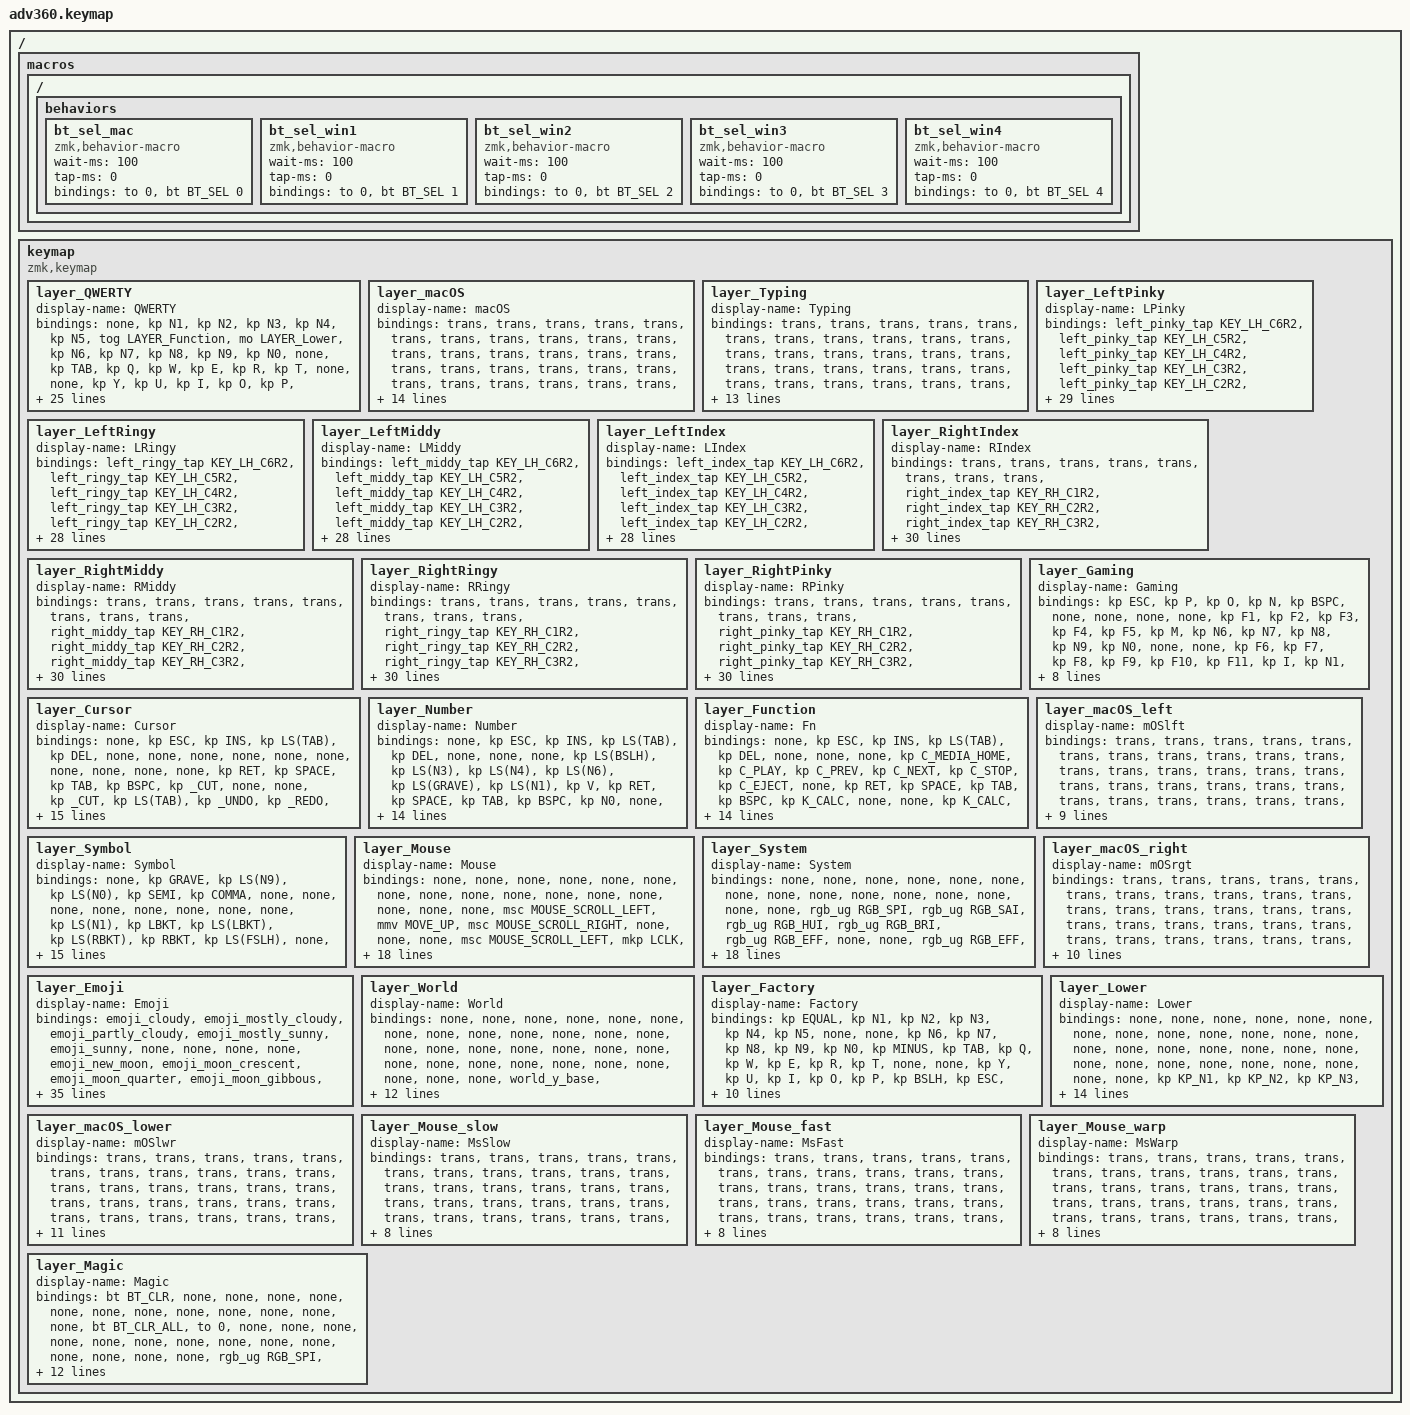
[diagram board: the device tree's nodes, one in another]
/*
 * Kinesis Advantage 360 Pro - Glorious Engrammer (QWERTY-only port)
 *
 * Ported from sunaku's Glove80 keymap v52 "Glorious Engrammer"
 * https://github.com/sunaku/glove80-keymaps
 *
 * SPDX-License-Identifier: MIT
 */

#include <behaviors.dtsi>
#include <dt-bindings/zmk/keys.h>
#include <dt-bindings/zmk/bt.h>
#include <dt-bindings/zmk/rgb.h>
#include <dt-bindings/zmk/outputs.h>
#include <dt-bindings/zmk/pointing.h>

#include "positions.h"

//////////////////////////////////////////////////////////////////////////////
//
// Layer index definitions (QWERTY-only: no Enthium/Colemak/Dvorak)
//
// v52 reordering: right finger layers reversed, Gaming moved up,
// Mouse/System swapped, Emoji/World moved after macOS_right,
// Mouse speed layers renamed (Mouse_slow/fast/warp).
//
//////////////////////////////////////////////////////////////////////////////

#define LAYER_QWERTY        0
#define LAYER_macOS          1
#define LAYER_Typing         2
#define LAYER_LeftPinky      3
#define LAYER_LeftRingy      4
#define LAYER_LeftMiddy      5
#define LAYER_LeftIndex      6
#define LAYER_RightIndex     7
#define LAYER_RightMiddy     8
#define LAYER_RightRingy     9
#define LAYER_RightPinky    10
#define LAYER_Gaming        11
#define LAYER_Cursor        12
#define LAYER_Number        13
#define LAYER_Function      14
#define LAYER_macOS_left    15
#define LAYER_Symbol        16
#define LAYER_Mouse         17
#define LAYER_System        18
#define LAYER_macOS_right   19
#define LAYER_Emoji         20
#define LAYER_World         21
#define LAYER_Factory       22
#define LAYER_Lower         23
#define LAYER_macOS_lower   24
#define LAYER_Mouse_slow    25
#define LAYER_Mouse_fast    26
#define LAYER_Mouse_warp    27
#define LAYER_Magic         28


//////////////////////////////////////////////////////////////////////////////
//
// Behaviors, macros, combos, and conditional layers are in keymap.dtsi
//
//////////////////////////////////////////////////////////////////////////////

#define OPERATING_SYSTEM 'M'  // macOS: Cmd on middle finger, Ctrl on pinky
#define DIFFICULTY_LEVEL  5   // expert (100ms tapping resolution)
#include "keymap.dtsi"

/ {
  macros {
    // BT profile 0: Mac (resets layers, base is already Mac, no toggle needed)
    ZMK_MACRO(bt_sel_mac,
      wait-ms = <100>;
      tap-ms = <0>;
      bindings = <&to 0 &bt BT_SEL 0>;
    )
    // BT profiles 1-4: Windows (resets layers, same Ctrl position as Mac)
    ZMK_MACRO(bt_sel_win1,
      wait-ms = <100>;
      tap-ms = <0>;
      bindings = <&to 0 &bt BT_SEL 1>;
    )
    ZMK_MACRO(bt_sel_win2,
      wait-ms = <100>;
      tap-ms = <0>;
      bindings = <&to 0 &bt BT_SEL 2>;
    )
    ZMK_MACRO(bt_sel_win3,
      wait-ms = <100>;
      tap-ms = <0>;
      bindings = <&to 0 &bt BT_SEL 3>;
    )
    ZMK_MACRO(bt_sel_win4,
      wait-ms = <100>;
      tap-ms = <0>;
      bindings = <&to 0 &bt BT_SEL 4>;
    )
  };

  keymap {
    compatible = "zmk,keymap";

    //////////////////////////////////////////////////////////////////////////
    //
    // Layer 0: QWERTY (base)
    //
    // v52 thumb cluster reorganization:
    //   T1 = Function ESC       T4 = Cursor BSPC
    //   T2 = Lower (hold only)  T5 = Number DEL
    //   T3 = PG_UP              T6 = PG_DN
    //
    //////////////////////////////////////////////////////////////////////////

    layer_QWERTY {
      display-name = "QWERTY";
      bindings = <
        // Row 0: numrow (Glove80 Row 2) + mod keys
        &none  &kp N1  &kp N2  &kp N3  &kp N4  &kp N5  &tog LAYER_Function                                                            &mo LAYER_Lower  &kp N6  &kp N7  &kp N8  &kp N9  &kp N0  &none
        // Row 1: QWERTY (Glove80 Row 3) + mod keys
        &kp TAB  &kp Q  &kp W  &kp E  &kp R  &kp T  &none                                                                                &none  &kp Y  &kp U  &kp I  &kp O  &kp P  &kp MINUS
        // Row 2: home row (Glove80 Row 4) + mod + palm (T5=Function ESC, T6=Lower DEL | T6=Lower INS, T5=System TAB)
        &kp EQUAL  &LeftPinky (A, LAYER_QWERTY)  &LeftRingy (S, LAYER_QWERTY)  &LeftMiddy (D, LAYER_QWERTY)  &LeftIndex (F, LAYER_QWERTY)  &kp G  &none    &thumb LAYER_Function ESC  &thumb LAYER_Lower DELETE    &thumb LAYER_Lower INSERT  &thumb LAYER_System TAB    &none  &kp H  &RightIndex (J, LAYER_QWERTY)  &RightMiddy (K, LAYER_QWERTY)  &RightRingy (L, LAYER_QWERTY)  &RightPinky (SEMI, LAYER_QWERTY)  &kp SQT
        // Row 3: lower row (Glove80 Row 5) + middle (T4=PG_UP | T4=thums_up)
        &sticky_key_modtap LSFT LSFT  &kp Z  &kp X  &kp C  &kp V  &kp B    &kp PG_UP                                      &thums_up    &kp N  &kp M  &kp COMMA  &kp DOT  &kp FSLH  &sticky_key_modtap RSFT RSFT
        // Row 4: bottom (Glove80 Row 6) + thumb (T1=Cursor BSPC, T2=LSFT, T3=Number PG_DN | T3=thums_down, T2=Mouse ENTER, T1=Symbol SPACE)
        &magic LAYER_Magic 0  &kp BSLH  &parang_left  &parang_right  &stumb LAYER_Emoji LSFT    &thumb LAYER_Cursor BACKSPACE  &kp LSFT  &thumb LAYER_Number PG_DN    &thums_down  &thumb LAYER_Mouse ENTER  &thumb LAYER_Symbol SPACE    &stumb LAYER_World RSFT  &kp LBKT  &kp RBKT  &kp GRAVE  &magic LAYER_Magic 0
      >;
    };

    //////////////////////////////////////////////////////////////////////////
    //
    // Layer 1: macOS
    //
    // Overlay that swaps home row mods to macOS-style (sticky HRMs)
    // and is otherwise transparent.
    //
    //////////////////////////////////////////////////////////////////////////

    layer_macOS {
      display-name = "macOS";
      bindings = <
        // Row 0
        &trans  &trans  &trans  &trans  &trans  &trans  &trans                                     &trans  &trans  &trans  &trans  &trans  &trans  &trans
        // Row 1
        &trans  &trans  &trans  &trans  &trans  &trans  &trans                                     &trans  &trans  &trans  &trans  &trans  &trans  &trans
        // Row 2: sticky HRMs overridden for macOS
        &trans  &LeftMiddy_layer0 (KEY_LH_C5R4)  &LeftRingy_layer0 (KEY_LH_C4R4)  &LeftPinky_layer0 (KEY_LH_C3R4)  &LeftIndex_layer0 (KEY_LH_C2R4)  &trans  &trans    &trans  &trans    &trans  &trans    &trans  &trans  &RightIndex_layer0 (KEY_RH_C2R4)  &RightPinky_layer0 (KEY_RH_C3R4)  &RightRingy_layer0 (KEY_RH_C4R4)  &RightMiddy_layer0 (KEY_RH_C5R4)  &trans
        // Row 3
        &trans  &trans  &trans  &trans  &trans  &trans    &trans                                   &trans    &trans  &trans  &trans  &trans  &trans  &trans
        // Row 4
        &trans  &trans  &trans  &trans  &trans    &trans  &trans  &trans    &trans  &trans  &trans    &trans  &trans  &trans  &trans  &trans
      >;
    };

    //////////////////////////////////////////////////////////////////////////
    //
    // Layer 2: Typing
    //
    // Disables home row mods for pure typing (plain keys on home row).
    // Disables layer-tap on thumb keys too.
    // v52: T2 is now &mo LAYER_Lower (no tap key), so &trans on T2.
    //      T6 is now &kp PG_DN, so kp KEY_LH/RH_T6 works.
    //
    //////////////////////////////////////////////////////////////////////////

    layer_Typing {
      display-name = "Typing";
      bindings = <
        // Row 0
        &trans  &trans  &trans  &trans  &trans  &trans  &trans                                     &trans  &trans  &trans  &trans  &trans  &trans  &trans
        // Row 1
        &trans  &trans  &trans  &trans  &trans  &trans  &trans                                     &trans  &trans  &trans  &trans  &trans  &trans  &trans
        // Row 2: plain keys instead of HRMs + plain thumb tap keys on palm (T5, T6)
        &trans  &kp LEFT_PINKY_KEY  &kp LEFT_RINGY_KEY  &kp LEFT_MIDDY_KEY  &kp LEFT_INDEX_KEY  &trans  &trans    &kp KEY_LH_T5  &trans    &trans  &kp KEY_RH_T5    &trans  &trans  &kp RIGHT_INDEX_KEY  &kp RIGHT_MIDDY_KEY  &kp RIGHT_RINGY_KEY  &kp RIGHT_PINKY_KEY  &trans
        // Row 3: plain thumb keys on middle (T4)
        &trans  &trans  &trans  &trans  &trans  &trans    &kp KEY_LH_T4                           &kp KEY_RH_T4    &trans  &trans  &trans  &trans  &trans  &trans
        // Row 4: plain thumb keys on T1, T3 (T2 is &mo, no tap key → &trans)
        &trans  &trans  &trans  &trans  &kp KEY_LH_C2R6    &kp KEY_LH_T1  &trans  &trans    &trans  &trans  &kp KEY_RH_T1    &kp KEY_RH_C2R6  &trans  &trans  &trans  &trans
      >;
    };

    //////////////////////////////////////////////////////////////////////////
    //
    // Layer 3: LeftPinky (bilateral enforcement)
    //
    //////////////////////////////////////////////////////////////////////////

    layer_LeftPinky {
      display-name = "LPinky";
      bindings = <
        // Row 0 (Glove80 Row 2)
        &left_pinky_tap KEY_LH_C6R2  &left_pinky_tap KEY_LH_C5R2  &left_pinky_tap KEY_LH_C4R2  &left_pinky_tap KEY_LH_C3R2  &left_pinky_tap KEY_LH_C2R2  &left_pinky_tap KEY_LH_C1R2  &trans                                     &trans  &trans  &trans  &trans  &trans  &trans  &trans
        // Row 1 (Glove80 Row 3)
        &left_pinky_tap KEY_LH_C6R3  &left_pinky_tap KEY_LH_C5R3  &left_pinky_tap KEY_LH_C4R3  &left_pinky_tap KEY_LH_C3R3  &left_pinky_tap KEY_LH_C2R3  &left_pinky_tap KEY_LH_C1R3  &trans                                     &trans  &trans  &trans  &trans  &trans  &trans  &trans
        // Row 2: home row + palm (T5, T6); pinky = &none
        &left_pinky_tap KEY_LH_C6R4  &none  &LeftPinkyRingy  &LeftPinkyMiddy  &LeftPinkyIndex  &left_pinky_tap KEY_LH_C1R4  &trans    &mo LAY_LH_T5  &left_pinky_tap KEY_LH_T6    &trans  &trans    &trans  &trans  &kp RIGHT_INDEX_KEY  &kp RIGHT_MIDDY_KEY  &kp RIGHT_RINGY_KEY  &kp RIGHT_PINKY_KEY  &trans
        // Row 3 (Glove80 Row 5) + middle (T4)
        &trans  &left_pinky_tap KEY_LH_C5R5  &left_pinky_tap KEY_LH_C4R5  &left_pinky_tap KEY_LH_C3R5  &left_pinky_tap KEY_LH_C2R5  &left_pinky_tap KEY_LH_C1R5    &mo LAY_LH_T4                                     &trans    &trans  &trans  &trans  &trans  &trans  &trans
        // Row 4 (Glove80 Row 6 + thumb T1-T3); v52: T2 = &mo LAY_LH_T2 (was &left_pinky_tap)
        &trans  &left_pinky_tap KEY_LH_C5R6  &left_pinky_tap KEY_LH_C4R6  &left_pinky_tap KEY_LH_C3R6  &mo LAY_LH_C2R6    &mo LAY_LH_T1  &mo LAY_LH_T2  &left_pinky_tap KEY_LH_T3    &trans  &trans  &trans    &trans  &trans  &trans  &trans  &trans
      >;
    };

    //////////////////////////////////////////////////////////////////////////
    //
    // Layer 4: LeftRingy (bilateral enforcement)
    //
    //////////////////////////////////////////////////////////////////////////

    layer_LeftRingy {
      display-name = "LRingy";
      bindings = <
        // Row 0
        &left_ringy_tap KEY_LH_C6R2  &left_ringy_tap KEY_LH_C5R2  &left_ringy_tap KEY_LH_C4R2  &left_ringy_tap KEY_LH_C3R2  &left_ringy_tap KEY_LH_C2R2  &left_ringy_tap KEY_LH_C1R2  &trans                                     &trans  &trans  &trans  &trans  &trans  &trans  &trans
        // Row 1
        &left_ringy_tap KEY_LH_C6R3  &left_ringy_tap KEY_LH_C5R3  &left_ringy_tap KEY_LH_C4R3  &left_ringy_tap KEY_LH_C3R3  &left_ringy_tap KEY_LH_C2R3  &left_ringy_tap KEY_LH_C1R3  &trans                                     &trans  &trans  &trans  &trans  &trans  &trans  &trans
        // Row 2: home row + palm; ringy = &none
        &left_ringy_tap KEY_LH_C6R4  &LeftRingyPinky  &none  &LeftRingyMiddy  &LeftRingyIndex  &left_ringy_tap KEY_LH_C1R4  &trans    &mo LAY_LH_T5  &left_ringy_tap KEY_LH_T6    &trans  &trans    &trans  &trans  &kp RIGHT_INDEX_KEY  &kp RIGHT_MIDDY_KEY  &kp RIGHT_RINGY_KEY  &kp RIGHT_PINKY_KEY  &trans
        // Row 3
        &trans  &left_ringy_tap KEY_LH_C5R5  &left_ringy_tap KEY_LH_C4R5  &left_ringy_tap KEY_LH_C3R5  &left_ringy_tap KEY_LH_C2R5  &left_ringy_tap KEY_LH_C1R5    &mo LAY_LH_T4                                     &trans    &trans  &trans  &trans  &trans  &trans  &trans
        // Row 4: v52: T2 = &mo LAY_LH_T2
        &trans  &left_ringy_tap KEY_LH_C5R6  &left_ringy_tap KEY_LH_C4R6  &left_ringy_tap KEY_LH_C3R6  &mo LAY_LH_C2R6    &mo LAY_LH_T1  &mo LAY_LH_T2  &left_ringy_tap KEY_LH_T3    &trans  &trans  &trans    &trans  &trans  &trans  &trans  &trans
      >;
    };

    //////////////////////////////////////////////////////////////////////////
    //
    // Layer 5: LeftMiddy (bilateral enforcement)
    //
    //////////////////////////////////////////////////////////////////////////

    layer_LeftMiddy {
      display-name = "LMiddy";
      bindings = <
        // Row 0
        &left_middy_tap KEY_LH_C6R2  &left_middy_tap KEY_LH_C5R2  &left_middy_tap KEY_LH_C4R2  &left_middy_tap KEY_LH_C3R2  &left_middy_tap KEY_LH_C2R2  &left_middy_tap KEY_LH_C1R2  &trans                                     &trans  &trans  &trans  &trans  &trans  &trans  &trans
        // Row 1
        &left_middy_tap KEY_LH_C6R3  &left_middy_tap KEY_LH_C5R3  &left_middy_tap KEY_LH_C4R3  &left_middy_tap KEY_LH_C3R3  &left_middy_tap KEY_LH_C2R3  &left_middy_tap KEY_LH_C1R3  &trans                                     &trans  &trans  &trans  &trans  &trans  &trans  &trans
        // Row 2: home row + palm; middy = &none
        &left_middy_tap KEY_LH_C6R4  &LeftMiddyPinky  &LeftMiddyRingy  &none  &LeftMiddyIndex  &left_middy_tap KEY_LH_C1R4  &trans    &mo LAY_LH_T5  &left_middy_tap KEY_LH_T6    &trans  &trans    &trans  &trans  &kp RIGHT_INDEX_KEY  &kp RIGHT_MIDDY_KEY  &kp RIGHT_RINGY_KEY  &kp RIGHT_PINKY_KEY  &trans
        // Row 3
        &trans  &left_middy_tap KEY_LH_C5R5  &left_middy_tap KEY_LH_C4R5  &left_middy_tap KEY_LH_C3R5  &left_middy_tap KEY_LH_C2R5  &left_middy_tap KEY_LH_C1R5    &mo LAY_LH_T4                                     &trans    &trans  &trans  &trans  &trans  &trans  &trans
        // Row 4: v52: T2 = &mo LAY_LH_T2
        &trans  &left_middy_tap KEY_LH_C5R6  &left_middy_tap KEY_LH_C4R6  &left_middy_tap KEY_LH_C3R6  &mo LAY_LH_C2R6    &mo LAY_LH_T1  &mo LAY_LH_T2  &left_middy_tap KEY_LH_T3    &trans  &trans  &trans    &trans  &trans  &trans  &trans  &trans
      >;
    };

    //////////////////////////////////////////////////////////////////////////
    //
    // Layer 6: LeftIndex (bilateral enforcement)
    //
    //////////////////////////////////////////////////////////////////////////

    layer_LeftIndex {
      display-name = "LIndex";
      bindings = <
        // Row 0
        &left_index_tap KEY_LH_C6R2  &left_index_tap KEY_LH_C5R2  &left_index_tap KEY_LH_C4R2  &left_index_tap KEY_LH_C3R2  &left_index_tap KEY_LH_C2R2  &left_index_tap KEY_LH_C1R2  &trans                                     &trans  &trans  &trans  &trans  &trans  &trans  &trans
        // Row 1
        &left_index_tap KEY_LH_C6R3  &left_index_tap KEY_LH_C5R3  &left_index_tap KEY_LH_C4R3  &left_index_tap KEY_LH_C3R3  &left_index_tap KEY_LH_C2R3  &left_index_tap KEY_LH_C1R3  &trans                                     &trans  &trans  &trans  &trans  &trans  &trans  &trans
        // Row 2: home row + palm; index = &none
        &left_index_tap KEY_LH_C6R4  &LeftIndexPinky  &LeftIndexRingy  &LeftIndexMiddy  &none  &left_index_tap KEY_LH_C1R4  &trans    &mo LAY_LH_T5  &left_index_tap KEY_LH_T6    &trans  &trans    &trans  &trans  &kp RIGHT_INDEX_KEY  &kp RIGHT_MIDDY_KEY  &kp RIGHT_RINGY_KEY  &kp RIGHT_PINKY_KEY  &trans
        // Row 3
        &trans  &left_index_tap KEY_LH_C5R5  &left_index_tap KEY_LH_C4R5  &left_index_tap KEY_LH_C3R5  &left_index_tap KEY_LH_C2R5  &left_index_tap KEY_LH_C1R5    &mo LAY_LH_T4                                     &trans    &trans  &trans  &trans  &trans  &trans  &trans
        // Row 4: v52: T2 = &mo LAY_LH_T2
        &trans  &left_index_tap KEY_LH_C5R6  &left_index_tap KEY_LH_C4R6  &left_index_tap KEY_LH_C3R6  &mo LAY_LH_C2R6    &mo LAY_LH_T1  &mo LAY_LH_T2  &left_index_tap KEY_LH_T3    &trans  &trans  &trans    &trans  &trans  &trans  &trans  &trans
      >;
    };

    //////////////////////////////////////////////////////////////////////////
    //
    // Layer 7: RightIndex (bilateral enforcement)
    //
    // v52: reversed order (was layer 10, now layer 7)
    //
    //////////////////////////////////////////////////////////////////////////

    layer_RightIndex {
      display-name = "RIndex";
      bindings = <
        // Row 0
        &trans  &trans  &trans  &trans  &trans  &trans  &trans                                     &trans  &right_index_tap KEY_RH_C1R2  &right_index_tap KEY_RH_C2R2  &right_index_tap KEY_RH_C3R2  &right_index_tap KEY_RH_C4R2  &right_index_tap KEY_RH_C5R2  &right_index_tap KEY_RH_C6R2
        // Row 1
        &trans  &trans  &trans  &trans  &trans  &trans  &trans                                     &trans  &right_index_tap KEY_RH_C1R3  &right_index_tap KEY_RH_C2R3  &right_index_tap KEY_RH_C3R3  &right_index_tap KEY_RH_C4R3  &right_index_tap KEY_RH_C5R3  &right_index_tap KEY_RH_C6R3
        // Row 2: home row + palm; index = &none
        &trans  &kp LEFT_PINKY_KEY  &kp LEFT_RINGY_KEY  &kp LEFT_MIDDY_KEY  &kp LEFT_INDEX_KEY  &trans  &trans    &trans  &trans    &right_index_tap KEY_RH_T6  &mo LAY_RH_T5    &trans  &right_index_tap KEY_RH_C1R4  &none  &RightIndexMiddy  &RightIndexRingy  &RightIndexPinky  &right_index_tap KEY_RH_C6R4
        // Row 3
        &trans  &trans  &trans  &trans  &trans  &trans    &trans                                   &mo LAY_RH_T4    &right_index_tap KEY_RH_C1R5  &right_index_tap KEY_RH_C2R5  &right_index_tap KEY_RH_C3R5  &right_index_tap KEY_RH_C4R5  &right_index_tap KEY_RH_C5R5  &trans
        // Row 4: v52: T2 = &mo LAY_RH_T2 (was &right_index_tap)
        &trans  &trans  &trans  &trans  &trans    &trans  &trans  &trans    &right_index_tap KEY_RH_T3  &mo LAY_RH_T2  &mo LAY_RH_T1    &mo LAY_RH_C2R6  &right_index_tap KEY_RH_C3R6  &right_index_tap KEY_RH_C4R6  &right_index_tap KEY_RH_C5R6  &trans
      >;
    };

    //////////////////////////////////////////////////////////////////////////
    //
    // Layer 8: RightMiddy (bilateral enforcement)
    //
    //////////////////////////////////////////////////////////////////////////

    layer_RightMiddy {
      display-name = "RMiddy";
      bindings = <
        // Row 0
        &trans  &trans  &trans  &trans  &trans  &trans  &trans                                     &trans  &right_middy_tap KEY_RH_C1R2  &right_middy_tap KEY_RH_C2R2  &right_middy_tap KEY_RH_C3R2  &right_middy_tap KEY_RH_C4R2  &right_middy_tap KEY_RH_C5R2  &right_middy_tap KEY_RH_C6R2
        // Row 1
        &trans  &trans  &trans  &trans  &trans  &trans  &trans                                     &trans  &right_middy_tap KEY_RH_C1R3  &right_middy_tap KEY_RH_C2R3  &right_middy_tap KEY_RH_C3R3  &right_middy_tap KEY_RH_C4R3  &right_middy_tap KEY_RH_C5R3  &right_middy_tap KEY_RH_C6R3
        // Row 2: home row + palm; middy = &none
        &trans  &kp LEFT_PINKY_KEY  &kp LEFT_RINGY_KEY  &kp LEFT_MIDDY_KEY  &kp LEFT_INDEX_KEY  &trans  &trans    &trans  &trans    &right_middy_tap KEY_RH_T6  &mo LAY_RH_T5    &trans  &right_middy_tap KEY_RH_C1R4  &RightMiddyIndex  &none  &RightMiddyRingy  &RightMiddyPinky  &right_middy_tap KEY_RH_C6R4
        // Row 3
        &trans  &trans  &trans  &trans  &trans  &trans    &trans                                   &mo LAY_RH_T4    &right_middy_tap KEY_RH_C1R5  &right_middy_tap KEY_RH_C2R5  &right_middy_tap KEY_RH_C3R5  &right_middy_tap KEY_RH_C4R5  &right_middy_tap KEY_RH_C5R5  &trans
        // Row 4: v52: T2 = &mo LAY_RH_T2
        &trans  &trans  &trans  &trans  &trans    &trans  &trans  &trans    &right_middy_tap KEY_RH_T3  &mo LAY_RH_T2  &mo LAY_RH_T1    &mo LAY_RH_C2R6  &right_middy_tap KEY_RH_C3R6  &right_middy_tap KEY_RH_C4R6  &right_middy_tap KEY_RH_C5R6  &trans
      >;
    };

    //////////////////////////////////////////////////////////////////////////
    //
    // Layer 9: RightRingy (bilateral enforcement)
    //
    //////////////////////////////////////////////////////////////////////////

    layer_RightRingy {
      display-name = "RRingy";
      bindings = <
        // Row 0
        &trans  &trans  &trans  &trans  &trans  &trans  &trans                                     &trans  &right_ringy_tap KEY_RH_C1R2  &right_ringy_tap KEY_RH_C2R2  &right_ringy_tap KEY_RH_C3R2  &right_ringy_tap KEY_RH_C4R2  &right_ringy_tap KEY_RH_C5R2  &right_ringy_tap KEY_RH_C6R2
        // Row 1
        &trans  &trans  &trans  &trans  &trans  &trans  &trans                                     &trans  &right_ringy_tap KEY_RH_C1R3  &right_ringy_tap KEY_RH_C2R3  &right_ringy_tap KEY_RH_C3R3  &right_ringy_tap KEY_RH_C4R3  &right_ringy_tap KEY_RH_C5R3  &right_ringy_tap KEY_RH_C6R3
        // Row 2: home row + palm; ringy = &none
        &trans  &kp LEFT_PINKY_KEY  &kp LEFT_RINGY_KEY  &kp LEFT_MIDDY_KEY  &kp LEFT_INDEX_KEY  &trans  &trans    &trans  &trans    &right_ringy_tap KEY_RH_T6  &mo LAY_RH_T5    &trans  &right_ringy_tap KEY_RH_C1R4  &RightRingyIndex  &RightRingyMiddy  &none  &RightRingyPinky  &right_ringy_tap KEY_RH_C6R4
        // Row 3
        &trans  &trans  &trans  &trans  &trans  &trans    &trans                                   &mo LAY_RH_T4    &right_ringy_tap KEY_RH_C1R5  &right_ringy_tap KEY_RH_C2R5  &right_ringy_tap KEY_RH_C3R5  &right_ringy_tap KEY_RH_C4R5  &right_ringy_tap KEY_RH_C5R5  &trans
        // Row 4: v52: T2 = &mo LAY_RH_T2
        &trans  &trans  &trans  &trans  &trans    &trans  &trans  &trans    &right_ringy_tap KEY_RH_T3  &mo LAY_RH_T2  &mo LAY_RH_T1    &mo LAY_RH_C2R6  &right_ringy_tap KEY_RH_C3R6  &right_ringy_tap KEY_RH_C4R6  &right_ringy_tap KEY_RH_C5R6  &trans
      >;
    };

    //////////////////////////////////////////////////////////////////////////
    //
    // Layer 10: RightPinky (bilateral enforcement)
    //
    //////////////////////////////////////////////////////////////////////////

    layer_RightPinky {
      display-name = "RPinky";
      bindings = <
        // Row 0
        &trans  &trans  &trans  &trans  &trans  &trans  &trans                                     &trans  &right_pinky_tap KEY_RH_C1R2  &right_pinky_tap KEY_RH_C2R2  &right_pinky_tap KEY_RH_C3R2  &right_pinky_tap KEY_RH_C4R2  &right_pinky_tap KEY_RH_C5R2  &right_pinky_tap KEY_RH_C6R2
        // Row 1
        &trans  &trans  &trans  &trans  &trans  &trans  &trans                                     &trans  &right_pinky_tap KEY_RH_C1R3  &right_pinky_tap KEY_RH_C2R3  &right_pinky_tap KEY_RH_C3R3  &right_pinky_tap KEY_RH_C4R3  &right_pinky_tap KEY_RH_C5R3  &right_pinky_tap KEY_RH_C6R3
        // Row 2: home row + palm; pinky = &none
        &trans  &kp LEFT_PINKY_KEY  &kp LEFT_RINGY_KEY  &kp LEFT_MIDDY_KEY  &kp LEFT_INDEX_KEY  &trans  &trans    &trans  &trans    &right_pinky_tap KEY_RH_T6  &mo LAY_RH_T5    &trans  &right_pinky_tap KEY_RH_C1R4  &RightPinkyIndex  &RightPinkyMiddy  &RightPinkyRingy  &none  &right_pinky_tap KEY_RH_C6R4
        // Row 3
        &trans  &trans  &trans  &trans  &trans  &trans    &trans                                   &mo LAY_RH_T4    &right_pinky_tap KEY_RH_C1R5  &right_pinky_tap KEY_RH_C2R5  &right_pinky_tap KEY_RH_C3R5  &right_pinky_tap KEY_RH_C4R5  &right_pinky_tap KEY_RH_C5R5  &trans
        // Row 4: v52: T2 = &mo LAY_RH_T2
        &trans  &trans  &trans  &trans  &trans    &trans  &trans  &trans    &right_pinky_tap KEY_RH_T3  &mo LAY_RH_T2  &mo LAY_RH_T1    &mo LAY_RH_C2R6  &right_pinky_tap KEY_RH_C3R6  &right_pinky_tap KEY_RH_C4R6  &right_pinky_tap KEY_RH_C5R6  &trans
      >;
    };

    //////////////////////////////////////////////////////////////////////////
    //
    // Layer 11: Gaming (v52: moved from 22 to 11)
    //
    //////////////////////////////////////////////////////////////////////////

    layer_Gaming {
      display-name = "Gaming";
      bindings = <
        // Row 0
        &kp ESC  &kp P  &kp O  &kp N  &kp BSPC  &none  &none                                                &none  &none  &kp F1  &kp F2  &kp F3  &kp F4  &kp F5
        // Row 1
        &kp M  &kp N6  &kp N7  &kp N8  &kp N9  &kp N0  &none                                                &none  &kp F6  &kp F7  &kp F8  &kp F9  &kp F10  &kp F11
        // Row 2
        &kp I  &kp N1  &kp N2  &kp N3  &kp N4  &kp N5  &none    &none  &none    &none  &none    &none  &kp Y  &kp U  &kp I  &kp O  &kp P  &kp F12
        // Row 3
        &kp T  &kp TAB  &kp Q  &kp W  &kp E  &kp R    &none                                                  &none    &kp H  &kp J  &kp K  &kp L  &kp SEMI  &kp SQT
        // Row 4
        &kp G  &kp LSHFT  &kp A  &kp S  &kp D    &kp F  &kp LSHFT  &kp LALT    &kp V  &kp ESC  &kp UP    &kp RET  &kp N  &kp M  &kp COMMA  &kp DOT
      >;
    };

    //////////////////////////////////////////////////////////////////////////
    //
    // Layer 12: Cursor
    //
    // v52: content shifted up one row; new Row 6 content on bottom.
    //
    //////////////////////////////////////////////////////////////////////////

    layer_Cursor {
      display-name = "Cursor";
      bindings = <
        // Row 0 (from Glove80 Row 2)
        &none  &kp ESC  &kp INS  &kp LS(TAB)  &kp DEL  &none  &none                                                      &none  &none  &none  &none  &none  &none  &none
        // Row 1 (from Glove80 Row 3)
        &none  &kp RET  &kp SPACE  &kp TAB  &kp BSPC  &kp _CUT  &none                                                    &none  &kp _CUT  &kp LS(TAB)  &kp _UNDO  &kp _REDO  &kp TAB  &kp LA(LS(TAB))
        // Row 2: home row (Glove80 Row 4) + palm (T5=&none, T6=&none | T6=select_none, T5=extend_line)
        &sk LSHFT  &kp LEFT_PINKY_MOD  &kp LEFT_RINGY_MOD  &kp LEFT_MIDDY_MOD  &kp LEFT_INDEX_MOD  &kp _COPY  &none    &none  &none    &select_none  &extend_line    &none  &kp _COPY  &kp LEFT  &kp UP  &kp DOWN  &kp RIGHT  &sk LSHFT
        // Row 3: selection (Glove80 Row 5) + middle (T4=&none | T4=extend_word)
        &kp _C(L)  &select_all  &select_line  &select_word  &kp _FIND  &kp _PASTE    &none                                     &extend_word    &kp _PASTE  &kp _HOME  &kp PG_UP  &kp PG_DN  &kp _END  &kp _C(L)
        // Row 4: bottom (Glove80 Row 6) + thumb (T1=tog Cursor, T2=&none, T3=&none | T3=select_all, T2=select_line, T1=select_word)
        &kp _C(K)  &kp _UNDO  &kp _REDO  &kp _FIND_PREV  &kp _FIND_NEXT    &tog LAYER_Cursor  &none  &none    &select_all  &select_line  &select_word    &kp _FIND  &kp _FIND_PREV  &kp _FIND_NEXT  &kp _C(H)  &kp _C(K)
      >;
    };

    //////////////////////////////////////////////////////////////////////////
    //
    // Layer 13: Number
    //
    // v52: content shifted up; Row 1 hex display (A-E) dropped.
    //
    //////////////////////////////////////////////////////////////////////////

    layer_Number {
      display-name = "Number";
      bindings = <
        // Row 0 (from Glove80 Row 2)
        &none  &kp ESC  &kp INS  &kp LS(TAB)  &kp DEL  &none  &none                                                      &none  &kp LS(BSLH)  &kp LS(N3)  &kp LS(N4)  &kp LS(N6)  &kp LS(GRAVE)  &kp LS(N1)
        // Row 1 (from Glove80 Row 3)
        &kp V  &kp RET  &kp SPACE  &kp TAB  &kp BSPC  &kp N0  &none                                                      &none  &kp LS(G)  &kp N7  &kp N8  &kp N9  &kp LS(SEMI)  &kp LS(N5)
        // Row 2 (Glove80 Row 4) + palm (T5=&none, T6=&none | T6=LS(COMMA), T5=EQUAL)
        &sk LSHFT  &kp LEFT_PINKY_MOD  &kp LEFT_RINGY_MOD  &kp LEFT_MIDDY_MOD  &kp LEFT_INDEX_MOD  &kp X  &none    &none  &none    &kp LS(COMMA)  &kp EQUAL    &none  &kp K  &kp N4  &kp N5  &kp N6  &kp MINUS  &kp LS(EQUAL)
        // Row 3 (Glove80 Row 5) + middle (T4=&none | T4=COMMA)
        &kp E  &select_all  &select_line  &select_word  &kp _FIND  &kp F    &none                                     &kp COMMA    &kp J  &kp N1  &kp N2  &kp N3  &kp FSLH  &kp LS(N8)
        // Row 4: bottom (Glove80 Row 6) + thumb (T1=&none, T2=tog Number, T3=&none | T3=LS(DOT), T2=DOT, T1=N0)
        &kp LS(MINUS)  &kp _UNDO  &kp _REDO  &kp _FIND_PREV  &kp _FIND_NEXT    &none  &tog LAYER_Number  &none    &kp LS(DOT)  &kp DOT  &kp N0    &kp LS(N9)  &kp LBKT  &kp RBKT  &kp LS(N0)  &kp LS(N2)
      >;
    };

    //////////////////////////////////////////////////////////////////////////
    //
    // Layer 14: Function
    //
    //////////////////////////////////////////////////////////////////////////

    layer_Function {
      display-name = "Fn";
      bindings = <
        // Row 0 (from Glove80 Row 2)
        &none  &kp ESC  &kp INS  &kp LS(TAB)  &kp DEL  &none  &none                                                      &none  &kp C_MEDIA_HOME  &kp C_PLAY  &kp C_PREV  &kp C_NEXT  &kp C_STOP  &kp C_EJECT
        // Row 1 (from Glove80 Row 3)
        &none  &kp RET  &kp SPACE  &kp TAB  &kp BSPC  &kp K_CALC  &none                                                  &none  &kp K_CALC  &kp F7  &kp F8  &kp F9  &kp F10  &kp F13
        // Row 2 (Glove80 Row 4) + palm (T5=&none, T6=&none | T6=C_PREV, T5=C_PP)
        &sk LSHFT  &kp LEFT_PINKY_MOD  &kp LEFT_RINGY_MOD  &kp LEFT_MIDDY_MOD  &kp LEFT_INDEX_MOD  &kp K_WWW  &none    &none  &none    &kp C_PREV  &kp C_PP    &none  &kp K_WWW  &kp F4  &kp F5  &kp F6  &kp F11  &kp F14
        // Row 3 (Glove80 Row 5) + middle (T4=tog Function | T4=C_MUTE)
        &none  &select_all  &select_line  &select_word  &kp _FIND  &kp _FILES    &tog LAYER_Function                       &kp C_MUTE    &kp _FILES  &kp F1  &kp F2  &kp F3  &kp F12  &kp F15
        // Row 4: bottom (Glove80 Row 6) + thumb (T1=&none, T2=&none, T3=&none | T3=C_NEXT, T2=C_VOL_DN, T1=C_VOL_UP)
        &none  &kp _UNDO  &kp _REDO  &kp _FIND_PREV  &kp _FIND_NEXT    &none  &none  &none    &kp C_NEXT  &kp C_VOL_DN  &kp C_VOL_UP    &kp C_BRI_MAX  &kp C_BRI_UP  &kp C_BRI_DN  &kp C_BRI_MIN  &kp C_BRI_AUTO
      >;
    };

    //////////////////////////////////////////////////////////////////////////
    //
    // Layer 15: macOS_left (v52: moved from 25 to 15)
    //
    // Overrides left-hand sticky mods for macOS modifier order.
    //
    //////////////////////////////////////////////////////////////////////////

    layer_macOS_left {
      display-name = "mOSlft";
      bindings = <
        // Row 0
        &trans  &trans  &trans  &trans  &trans  &trans  &trans                                     &trans  &trans  &trans  &trans  &trans  &trans  &trans
        // Row 1
        &trans  &trans  &trans  &trans  &trans  &trans  &trans                                     &trans  &trans  &trans  &trans  &trans  &trans  &trans
        // Row 2: macOS-style mods on left home row
        &trans  &kp LEFT_MIDDY_MOD  &kp LEFT_RINGY_MOD  &kp LEFT_PINKY_MOD  &kp LEFT_INDEX_MOD  &trans  &trans    &trans  &trans    &trans  &trans    &trans  &trans  &trans  &trans  &trans  &trans  &trans
        // Row 3
        &trans  &trans  &trans  &trans  &trans  &trans    &trans                                   &trans    &trans  &trans  &trans  &trans  &trans  &trans
        // Row 4
        &trans  &trans  &trans  &trans  &trans    &trans  &trans  &trans    &trans  &trans  &trans    &trans  &trans  &trans  &trans  &trans
      >;
    };

    //////////////////////////////////////////////////////////////////////////
    //
    // Layer 16: Symbol
    //
    // v52: content shifted up; new Row 6 content on bottom.
    //
    //////////////////////////////////////////////////////////////////////////

    layer_Symbol {
      display-name = "Symbol";
      bindings = <
        // Row 0 (from Glove80 Row 2)
        &none  &kp GRAVE  &kp LS(N9)  &kp LS(N0)  &kp SEMI  &kp COMMA  &none                    &none  &none  &none  &none  &none  &none  &none
        // Row 1 (from Glove80 Row 3)
        &kp LS(N1)  &kp LBKT  &kp LS(LBKT)  &kp LS(RBKT)  &kp RBKT  &kp LS(FSLH)  &none        &none  &kp DOT  &kp DEL  &kp LS(TAB)  &kp INS  &kp ESC  &none
        // Row 2 (Glove80 Row 4) + palm (T5=DOT, T6=LS(N8) | T6=&none, T5=&none)
        &kp LS(N3)  &kp LS(N6)  &kp EQUAL  &kp LS(MINUS)  &kp LS(N4)  &kp LS(N8)  &none    &kp DOT  &kp LS(N8)    &none  &none    &none  &kp COMMA  &kp BSPC  &kp TAB  &kp SPACE  &kp RET  &triple_backtick
        // Row 3 (Glove80 Row 5) + middle (T4=BSLH | T4=&none)
        &kp LS(GRAVE)  &kp LS(COMMA)  &kp LS(BSLH)  &kp MINUS  &kp LS(DOT)  &kp FSLH    &kp BSLH                       &none    &kp SEMI  &kp LS(SINGLE_QUOTE)  &kp SQT  &kp GRAVE  &kp BSLH  &trans
        // Row 4: bottom (Glove80 Row 6) + thumb
        &dot_dot  &kp LS(N7)  &kp SQT  &kp LS(SQT)  &kp LS(EQUAL)    &kp LS(N5)  &kp LS(SEMI)  &kp LS(N2)    &none  &none  &tog LAYER_Symbol    &kp RIGHT_INDEX_MOD  &kp RIGHT_MIDDY_MOD  &kp RIGHT_RINGY_MOD  &kp RIGHT_PINKY_MOD  &none
      >;
    };

    //////////////////////////////////////////////////////////////////////////
    //
    // Layer 17: Mouse (v52: swapped with System, was 18 now 17)
    //
    // v52: speed layer refs renamed to Mouse_slow/fast/warp,
    //      speed toggle order changed on Row 4/5.
    //
    //////////////////////////////////////////////////////////////////////////

    layer_Mouse {
      display-name = "Mouse";
      bindings = <
        // Row 0 (from Glove80 Row 2)
        &none  &none  &none  &none  &none  &none  &none                                                      &none  &none  &none  &none  &none  &none  &none
        // Row 1 (from Glove80 Row 3): scroll + click
        &none  &none  &msc MOUSE_SCROLL_LEFT  &mmv MOVE_UP  &msc MOUSE_SCROLL_RIGHT  &none  &none            &none  &msc MOUSE_SCROLL_LEFT  &mkp LCLK  &mkp MCLK  &mkp RCLK  &msc MOUSE_SCROLL_RIGHT  &none
        // Row 2 (Glove80 Row 4) + palm (T5=K_APP, T6=MB5 | T6=_CUT, T5=_COPY): movement + speed layers
        &none  &msc MOUSE_SCROLL_UP  &mmv MOVE_LEFT  &mmv MOVE_DOWN  &mmv MOVE_RIGHT  &msc MOUSE_SCROLL_UP  &none    &kp K_APP  &mkp MB5    &kp _CUT  &kp _COPY    &none  &msc MOUSE_SCROLL_UP  &mo LAYER_Mouse_fast  &mo LAYER_Mouse_warp  &mo LAYER_Mouse_slow  &kp K_APP  &mkp MB4
        // Row 3 (Glove80 Row 5) + middle (T4=MCLK | T4=_PASTE): speed toggles + movement
        &none  &msc MOUSE_SCROLL_DOWN  &mo LAYER_Mouse_slow  &mo LAYER_Mouse_warp  &mo LAYER_Mouse_fast  &msc MOUSE_SCROLL_DOWN    &mkp MCLK                                     &kp _PASTE    &msc MOUSE_SCROLL_DOWN  &mmv MOVE_LEFT  &mmv MOVE_UP  &mmv MOVE_DOWN  &mmv MOVE_RIGHT  &mkp MB5
        // Row 4 (Glove80 Row 6) + thumb (T1=LCLK, T2=RCLK, T3=MB4 | T3=&none, T2=tog Mouse, T1=&none): clipboard + mods
        &none  &none  &kp _CUT  &kp _COPY  &kp _PASTE    &mkp LCLK  &mkp RCLK  &mkp MB4    &none  &tog LAYER_Mouse  &none    &kp RIGHT_INDEX_MOD  &kp RIGHT_MIDDY_MOD  &kp RIGHT_RINGY_MOD  &kp RIGHT_PINKY_MOD  &none
      >;
    };

    //////////////////////////////////////////////////////////////////////////
    //
    // Layer 18: System (v52: swapped with Mouse, was 17 now 18)
    //
    //////////////////////////////////////////////////////////////////////////

    layer_System {
      display-name = "System";
      bindings = <
        // Row 0 (from Glove80 Row 2)
        &none  &none  &none  &none  &none  &none  &none                                                      &none  &none  &none  &none  &none  &none  &none
        // Row 1 (from Glove80 Row 3): RGB forward controls
        &none  &rgb_ug RGB_SPI  &rgb_ug RGB_SAI  &rgb_ug RGB_HUI  &rgb_ug RGB_BRI  &rgb_ug RGB_EFF  &none    &none  &rgb_ug RGB_EFF  &rgb_ug RGB_BRI  &rgb_ug RGB_HUI  &rgb_ug RGB_SAI  &rgb_ug RGB_SPI  &none
        // Row 2 (Glove80 Row 4) + palm (T5=_SLEEP, T6=_POWER | T6=&none, T5=linux_magic_sysrq): RGB reverse
        &none  &rgb_ug RGB_SPD  &rgb_ug RGB_SAD  &rgb_ug RGB_HUD  &rgb_ug RGB_BRD  &rgb_ug RGB_EFR  &none    &kp _SLEEP  &kp _POWER    &none  &linux_magic_sysrq    &none  &rgb_ug RGB_EFR  &rgb_ug RGB_BRD  &rgb_ug RGB_HUD  &rgb_ug RGB_SAD  &rgb_ug RGB_SPD  &none
        // Row 3 (Glove80 Row 5) + middle (T4=_LOCK | T4=tog System): system keys
        &none  &none  &kp K_APP  &kp PSCRN  &kp PAUSE_BREAK  &rgb_ug RGB_TOG    &kp _LOCK                                     &tog LAYER_System    &rgb_ug RGB_TOG  &kp SLCK  &kp KP_NUM  &kp CAPS  &kp _LOCK  &kp _SLEEP
        // Row 4 (Glove80 Row 6) + thumb (T1=SLCK, T2=KP_NUM, T3=CAPS | T3=K_APP, T2=PSCRN, T1=PAUSE_BREAK): sysrq + mods
        &none  &none  &none  &none  &linux_magic_sysrq    &kp SLCK  &kp KP_NUM  &kp CAPS    &kp K_APP  &kp PSCRN  &kp PAUSE_BREAK    &kp RIGHT_INDEX_MOD  &kp RIGHT_MIDDY_MOD  &kp RIGHT_RINGY_MOD  &kp RIGHT_PINKY_MOD  &kp _POWER
      >;
    };

    //////////////////////////////////////////////////////////////////////////
    //
    // Layer 19: macOS_right (v52: moved from 26 to 19)
    //
    // Overrides right-hand sticky mods for macOS modifier order.
    //
    //////////////////////////////////////////////////////////////////////////

    layer_macOS_right {
      display-name = "mOSrgt";
      bindings = <
        // Row 0
        &trans  &trans  &trans  &trans  &trans  &trans  &trans                                     &trans  &trans  &trans  &trans  &trans  &trans  &trans
        // Row 1
        &trans  &trans  &trans  &trans  &trans  &trans  &trans                                     &trans  &trans  &trans  &trans  &trans  &trans  &trans
        // Row 2
        &trans  &trans  &trans  &trans  &trans  &trans  &trans    &trans  &trans    &trans  &trans    &trans  &trans  &trans  &trans  &trans  &trans  &trans
        // Row 3
        &trans  &trans  &trans  &trans  &trans  &trans    &trans                                   &trans    &trans  &trans  &trans  &trans  &trans  &trans
        // Row 4: macOS-style mods on right bottom row
        &trans  &trans  &trans  &trans  &trans    &trans  &trans  &trans    &trans  &trans  &trans    &kp RIGHT_INDEX_MOD  &kp RIGHT_PINKY_MOD  &kp RIGHT_RINGY_MOD  &kp RIGHT_MIDDY_MOD  &trans
      >;
    };

    //////////////////////////////////////////////////////////////////////////
    //
    // Layer 20: Emoji (v52: moved from 14 to 20)
    //
    //////////////////////////////////////////////////////////////////////////

    layer_Emoji {
      display-name = "Emoji";
      bindings = <
        // Row 0
        &emoji_cloudy  &emoji_mostly_cloudy  &emoji_partly_cloudy  &emoji_mostly_sunny  &emoji_sunny  &none  &none                                     &none  &none  &emoji_new_moon  &emoji_moon_crescent  &emoji_moon_quarter  &emoji_moon_gibbous  &emoji_full_moon
        // Row 1
        &emoji_rainbow  &emoji_light_skin_tone  &emoji_medium_light_skin_tone  &emoji_medium_skin_tone  &emoji_medium_dark_skin_tone  &emoji_dark_skin_tone  &none                                     &none  &emoji_theme_party  &emoji_theme_love  &emoji_theme_nature  &emoji_theme_strength  &emoji_theme_effort  &emoji_theme_science
        // Row 2
        &emoji_left_arrow  &emoji_bald  &emoji_red_hair  &emoji_curly_hair  &emoji_white_hair  &emoji_right_arrow  &none    &none  &none    &none  &none    &none  &emoji_face_laugh  &emoji_face_smile  &emoji_face_eyes  &emoji_face_joke  &emoji_face_fear  &emoji_face_surprise
        // Row 3
        &emoji_male_sign  &emoji_hair_style_preset  &emoji_skin_tone_preset  &emoji_gender_sign_preset  &sk LSHFT  &emoji_female_sign    &none                                     &none    &emoji_gesture_attention  &emoji_gesture_approval  &emoji_gesture_gratitude  &emoji_gesture_anxiety  &emoji_gesture_despair  &emoji_gesture_curious
        // Row 4
        &emoji_old_man  &emoji_man  &emoji_boy  &emoji_girl  &emoji_woman    &emoji_old_woman  &emoji_cityscape  &emoji_cityscape_dusk    &emoji_cityscape_night  &emoji_theme_magic  &emoji_theme_space    &emoji_theme_awesome  &emoji_person_tipping_hand  &emoji_person_gesturing_ok  &emoji_person_bowing  &emoji_person_raising_hand
      >;
    };

    //////////////////////////////////////////////////////////////////////////
    //
    // Layer 21: World (v52: moved from 15 to 21)
    //
    //////////////////////////////////////////////////////////////////////////

    layer_World {
      display-name = "World";
      bindings = <
        // Row 0
        &none  &none  &none  &none  &none  &none  &none                                                      &none  &none  &none  &none  &none  &none  &none
        // Row 1
        &none  &none  &none  &none  &none  &none  &none                                                      &none  &none  &none  &none  &none  &none  &none
        // Row 2: accented vowels on left; sticky mods on right
        &none  &none  &world_y_base  &world_o_base  &world_u_base  &world_sign_angle  &none    &none  &none    &none  &none    &none  &none  &none  &sk LALT  &sk RALT  &none  &none
        // Row 3: consonants + accented vowels on left; sticky mods on right
        &none  &world_consonants_base  &world_i_base  &world_a_base  &world_e_base  &world_sign_dash    &none                                     &none    &none  &sk LSHFT  &sk LCTRL  &sk RCTRL  &sk RSHFT  &none
        // Row 4: currency + quotes on left; toggle on right
        &world_currency_base  &world_quotes_left_base  &world_sign_landmark  &world_sign_ordinal  &world_sign_exclaim    &world_sign_question  &none  &none    &none  &none  &none    &none  &tog LAYER_World  &none  &none  &none
      >;
    };

    //////////////////////////////////////////////////////////////////////////
    //
    // Layer 22: Factory
    //
    // Standard QWERTY factory-default-style layout for recovery.
    //
    //////////////////////////////////////////////////////////////////////////

    layer_Factory {
      display-name = "Factory";
      bindings = <
        // Row 0
        &kp EQUAL  &kp N1  &kp N2  &kp N3  &kp N4  &kp N5  &none                                            &none  &kp N6  &kp N7  &kp N8  &kp N9  &kp N0  &kp MINUS
        // Row 1
        &kp TAB  &kp Q  &kp W  &kp E  &kp R  &kp T  &none                                                   &none  &kp Y  &kp U  &kp I  &kp O  &kp P  &kp BSLH
        // Row 2
        &kp ESC  &kp A  &kp S  &kp D  &kp F  &kp G  &none    &kp LCTRL  &mo LAYER_Lower    &kp LGUI  &kp RCTRL    &none  &kp H  &kp J  &kp K  &kp L  &kp SEMI  &kp SQT
        // Row 3
        &kp GRAVE  &kp Z  &kp X  &kp C  &kp V  &kp B    &kp LSHFT                                           &kp RSHFT    &kp N  &kp M  &kp COMMA  &kp DOT  &kp FSLH  &kp PG_UP
        // Row 4
        &magic LAYER_Magic 0  &kp HOME  &kp END  &kp LEFT  &kp RIGHT    &kp BSPC  &kp DEL  &kp LALT    &kp RALT  &kp RET  &kp SPACE    &kp UP  &kp DOWN  &kp LBKT  &kp RBKT  &kp PG_DN
      >;
    };

    //////////////////////////////////////////////////////////////////////////
    //
    // Layer 23: Lower (v52: was 24, now 23)
    //
    // Keypad numbers, sticky mods, and layer toggles.
    //
    //////////////////////////////////////////////////////////////////////////

    layer_Lower {
      display-name = "Lower";
      bindings = <
        // Row 0
        &none  &none  &none  &none  &none  &none  &none                                                      &none  &none  &none  &none  &none  &none  &none
        // Row 1
        &none  &none  &none  &none  &none  &none  &none                                                      &none  &none  &none  &none  &none  &none  &none
        // Row 2: KP digits 1-5 on left; KP digits 6-0 on right
        &none  &kp KP_N1  &kp KP_N2  &kp KP_N3  &kp KP_N4  &kp KP_N5  &none    &none  &none    &none  &none    &none  &kp KP_N6  &kp KP_N7  &kp KP_N8  &kp KP_N9  &kp KP_N0  &none
        // Row 3: sticky mods on left; KP operators on right
        &none  &sk LEFT_PINKY_MOD  &sk LEFT_RINGY_MOD  &sk LEFT_MIDDY_MOD  &sk LEFT_INDEX_MOD  &kp KP_MINUS    &tog LAYER_Function                                     &tog LAYER_System    &kp KP_SLASH  &sk RIGHT_INDEX_MOD  &sk RIGHT_MIDDY_MOD  &sk RIGHT_RINGY_MOD  &sk RIGHT_PINKY_MOD  &none
        // Row 4: KP grouping + layer toggles
        &none  &kp KP_LPAR  &kp KP_COMMA  &kp KP_DOT  &kp KP_RPAR    &kp KP_PLUS  &none  &kp RALT    &kp RALT  &none  &none    &kp KP_MULTIPLY  &kp KP_NUM  &kp KP_CLEAR  &kp KP_EQUAL  &kp KP_ENTER
      >;
    };

    //////////////////////////////////////////////////////////////////////////
    //
    // Layer 24: macOS_lower (v52: was 27, now 24)
    //
    // Overrides sticky mods on both hands for macOS modifier order.
    //
    //////////////////////////////////////////////////////////////////////////

    layer_macOS_lower {
      display-name = "mOSlwr";
      bindings = <
        // Row 0
        &trans  &trans  &trans  &trans  &trans  &trans  &trans                                     &trans  &trans  &trans  &trans  &trans  &trans  &trans
        // Row 1
        &trans  &trans  &trans  &trans  &trans  &trans  &trans                                     &trans  &trans  &trans  &trans  &trans  &trans  &trans
        // Row 2
        &trans  &trans  &trans  &trans  &trans  &trans  &trans    &trans  &trans    &trans  &trans    &trans  &trans  &trans  &trans  &trans  &trans  &trans
        // Row 3: macOS-style mods on both home rows
        &trans  &kp LEFT_MIDDY_MOD  &kp LEFT_RINGY_MOD  &kp LEFT_PINKY_MOD  &kp LEFT_INDEX_MOD  &trans    &trans                                     &trans    &trans  &kp RIGHT_INDEX_MOD  &kp RIGHT_PINKY_MOD  &kp RIGHT_RINGY_MOD  &kp RIGHT_MIDDY_MOD  &trans
        // Row 4
        &trans  &trans  &trans  &trans  &trans    &trans  &trans  &trans    &trans  &trans  &trans    &trans  &trans  &trans  &trans  &trans
      >;
    };

    //////////////////////////////////////////////////////////////////////////
    //
    // Layer 25: Mouse_slow (v52: renamed from MouseSlow, was 19 now 25)
    //
    //////////////////////////////////////////////////////////////////////////

    layer_Mouse_slow {
      display-name = "MsSlow";
      bindings = <
        &trans  &trans  &trans  &trans  &trans  &trans  &trans                                     &trans  &trans  &trans  &trans  &trans  &trans  &trans
        &trans  &trans  &trans  &trans  &trans  &trans  &trans                                     &trans  &trans  &trans  &trans  &trans  &trans  &trans
        &trans  &trans  &trans  &trans  &trans  &trans  &trans    &trans  &trans    &trans  &trans    &trans  &trans  &trans  &trans  &trans  &trans  &trans
        &trans  &trans  &trans  &trans  &trans  &trans    &trans                                   &trans    &trans  &trans  &trans  &trans  &trans  &trans
        &trans  &trans  &trans  &trans  &trans    &trans  &trans  &trans    &trans  &trans  &trans    &trans  &trans  &trans  &trans  &trans
      >;
    };

    //////////////////////////////////////////////////////////////////////////
    //
    // Layer 26: Mouse_fast (v52: renamed from MouseFast, was 20 now 26)
    //
    //////////////////////////////////////////////////////////////////////////

    layer_Mouse_fast {
      display-name = "MsFast";
      bindings = <
        &trans  &trans  &trans  &trans  &trans  &trans  &trans                                     &trans  &trans  &trans  &trans  &trans  &trans  &trans
        &trans  &trans  &trans  &trans  &trans  &trans  &trans                                     &trans  &trans  &trans  &trans  &trans  &trans  &trans
        &trans  &trans  &trans  &trans  &trans  &trans  &trans    &trans  &trans    &trans  &trans    &trans  &trans  &trans  &trans  &trans  &trans  &trans
        &trans  &trans  &trans  &trans  &trans  &trans    &trans                                   &trans    &trans  &trans  &trans  &trans  &trans  &trans
        &trans  &trans  &trans  &trans  &trans    &trans  &trans  &trans    &trans  &trans  &trans    &trans  &trans  &trans  &trans  &trans
      >;
    };

    //////////////////////////////////////////////////////////////////////////
    //
    // Layer 27: Mouse_warp (v52: renamed from MouseWarp, was 21 now 27)
    //
    //////////////////////////////////////////////////////////////////////////

    layer_Mouse_warp {
      display-name = "MsWarp";
      bindings = <
        &trans  &trans  &trans  &trans  &trans  &trans  &trans                                     &trans  &trans  &trans  &trans  &trans  &trans  &trans
        &trans  &trans  &trans  &trans  &trans  &trans  &trans                                     &trans  &trans  &trans  &trans  &trans  &trans  &trans
        &trans  &trans  &trans  &trans  &trans  &trans  &trans    &trans  &trans    &trans  &trans    &trans  &trans  &trans  &trans  &trans  &trans  &trans
        &trans  &trans  &trans  &trans  &trans  &trans    &trans                                   &trans    &trans  &trans  &trans  &trans  &trans  &trans
        &trans  &trans  &trans  &trans  &trans    &trans  &trans  &trans    &trans  &trans  &trans    &trans  &trans  &trans  &trans  &trans
      >;
    };

    //////////////////////////////////////////////////////////////////////////
    //
    // Layer 28: Magic
    //
    // v52: removed &tog LAYER_Typing from numrow. Uses &to 0 + &tog macOS.
    //
    //////////////////////////////////////////////////////////////////////////

    layer_Magic {
      display-name = "Magic";
      bindings = <
        // Row 0: BT clear + profiles
        &bt BT_CLR  &none  &none  &none  &none  &none  &none                                                 &none  &none  &none  &none  &none  &none  &bt BT_CLR_ALL
        // Row 1: base layer select (QWERTY only, macOS toggle)
        &to 0  &none  &none  &none  &none  &none  &none                                                      &none  &none  &none  &none  &none  &none  &none
        // Row 2: RGB controls
        &none  &rgb_ug RGB_SPI  &rgb_ug RGB_SAI  &rgb_ug RGB_HUI  &rgb_ug RGB_BRI  &rgb_ug RGB_TOG  &none    &none  &none    &none  &none    &none  &none  &none  &none  &none  &none  &none
        // Row 3: RGB reverse + bootloader
        &bootloader  &rgb_ug RGB_SPD  &rgb_ug RGB_SAD  &rgb_ug RGB_HUD  &rgb_ug RGB_BRD  &rgb_ug RGB_EFF    &none                                     &none    &none  &none  &none  &none  &none  &bootloader
        // Row 4: reset + BT profiles (0=Mac, 1-4=Win) + USB output + factory
        &sys_reset  &bt_sel_mac  &bt_sel_win1  &bt_sel_win2  &bt_sel_win3    &bt_sel_win4  &out OUT_USB  &tog LAYER_Factory    &none  &none  &none    &none  &none  &none  &tog LAYER_macOS  &sys_reset
      >;
    };

  };
};
